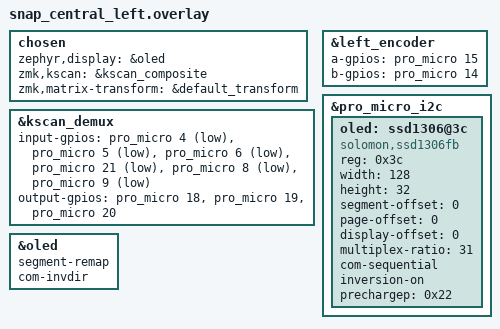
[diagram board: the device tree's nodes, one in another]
/*
 * Copyright (c) 2020 The ZMK Contributors
 *
 * SPDX-License-Identifier: MIT
 */

#include "snap.dtsi"
#include "snap.keymap"

chosen {
    zephyr,display = &oled;
    zmk,kscan = &kscan_composite;
    zmk,matrix-transform = &default_transform;
};

&kscan_demux {
    input-gpios
        = <&pro_micro 4  (GPIO_ACTIVE_LOW | GPIO_PULL_UP)>
        , <&pro_micro 5  (GPIO_ACTIVE_LOW | GPIO_PULL_UP)>
        , <&pro_micro 6  (GPIO_ACTIVE_LOW | GPIO_PULL_UP)>
        , <&pro_micro 21 (GPIO_ACTIVE_LOW | GPIO_PULL_UP)>
        , <&pro_micro 8  (GPIO_ACTIVE_LOW | GPIO_PULL_UP)>
        , <&pro_micro 9  (GPIO_ACTIVE_LOW | GPIO_PULL_UP)>
        ;
    output-gpios
        = <&pro_micro 18 GPIO_ACTIVE_HIGH>
        , <&pro_micro 19 GPIO_ACTIVE_HIGH>
        , <&pro_micro 20 GPIO_ACTIVE_HIGH>
        ;
};

&left_encoder {
    a-gpios = <&pro_micro 15 (GPIO_ACTIVE_HIGH | GPIO_PULL_UP)>;
    b-gpios = <&pro_micro 14 (GPIO_ACTIVE_HIGH | GPIO_PULL_UP)>;
    status = "okay";
};

&pro_micro_i2c {
    status = "okay";

    oled: ssd1306@3c {
        compatible = "solomon,ssd1306fb";
        reg = <0x3c>;
        width = <128>;
        height = <32>;
        segment-offset = <0>;
        page-offset = <0>;
        display-offset = <0>;
        multiplex-ratio = <31>;
        com-sequential;
        inversion-on;
        prechargep = <0x22>;
    };
};

&oled {
    segment-remap;
    com-invdir;
};
